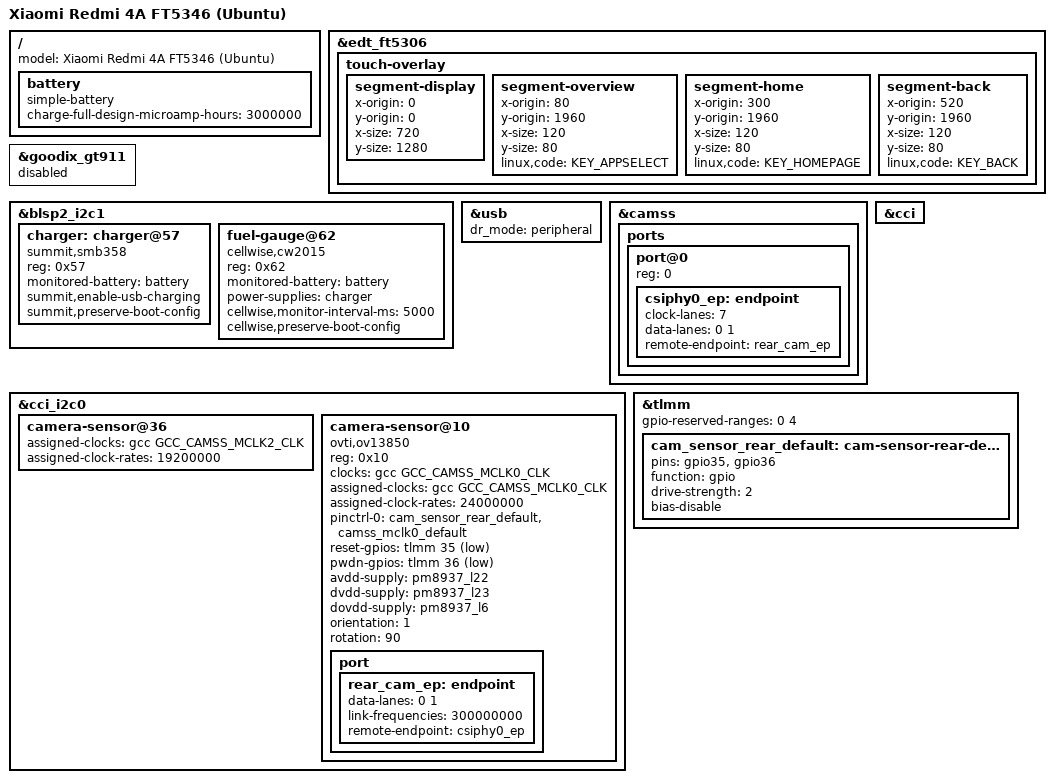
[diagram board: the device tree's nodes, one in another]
// SPDX-License-Identifier: GPL-2.0-only
/* Complete upstream rolex platform with this phone's board differences. */
#include "msm8917-xiaomi-rolex.dts"

/ {
	model = "Xiaomi Redmi 4A FT5346 (Ubuntu)";

	battery: battery {
		compatible = "simple-battery";
		charge-full-design-microamp-hours = <3000000>;
	};
};

&edt_ft5306 {
	status = "okay";

	/* FT5346 firmware reports printed keys at Y=2000, outside the LCD. */
	touch-overlay {
		segment-display {
			x-origin = <0>;
			y-origin = <0>;
			x-size = <720>;
			y-size = <1280>;
		};
		segment-overview {
			x-origin = <80>;
			y-origin = <1960>;
			x-size = <120>;
			y-size = <80>;
			linux,code = <KEY_APPSELECT>;
		};
		segment-home {
			x-origin = <300>;
			y-origin = <1960>;
			x-size = <120>;
			y-size = <80>;
			linux,code = <KEY_HOMEPAGE>;
		};
		segment-back {
			x-origin = <520>;
			y-origin = <1960>;
			x-size = <120>;
			y-size = <80>;
			linux,code = <KEY_BACK>;
		};
	};
};

&goodix_gt911 {
	status = "disabled";
};

&blsp2_i2c1 {
	status = "okay";

	charger: charger@57 {
		compatible = "summit,smb358";
		reg = <0x57>;
		monitored-battery = <&battery>;
		summit,enable-usb-charging;
		summit,preserve-boot-config;
	};

	fuel-gauge@62 {
		compatible = "cellwise,cw2015";
		reg = <0x62>;
		monitored-battery = <&battery>;
		power-supplies = <&charger>;
		cellwise,monitor-interval-ms = <5000>;
		cellwise,preserve-boot-config;
	};
};

&usb {
	dr_mode = "peripheral";
};

&camss {
	status = "okay";
	ports {
		port@0 {
			reg = <0>;
			csiphy0_ep: endpoint {
				clock-lanes = <7>;
				data-lanes = <0 1>;
				remote-endpoint = <&rear_cam_ep>;
			};
		};
	};
};

&cci {
	status = "okay";
};

&cci_i2c0 {
	/* The upstream front sensor requires a 19.2 MHz MCLK. */
	camera-sensor@36 {
		assigned-clocks = <&gcc GCC_CAMSS_MCLK2_CLK>;
		assigned-clock-rates = <19200000>;
	};

	/* OEM rear camera: CCI0, 8-bit address 0x20, MCLK0 and CSI0. */
	camera-sensor@10 {
		compatible = "ovti,ov13850";
		reg = <0x10>;
		clocks = <&gcc GCC_CAMSS_MCLK0_CLK>;
		clock-names = "xvclk";
		assigned-clocks = <&gcc GCC_CAMSS_MCLK0_CLK>;
		assigned-clock-rates = <24000000>;
		pinctrl-0 = <&cam_sensor_rear_default>, <&camss_mclk0_default>;
		pinctrl-names = "default";
		reset-gpios = <&tlmm 35 GPIO_ACTIVE_LOW>;
		pwdn-gpios = <&tlmm 36 GPIO_ACTIVE_LOW>;
		avdd-supply = <&pm8937_l22>;
		dvdd-supply = <&pm8937_l23>;
		dovdd-supply = <&pm8937_l6>;
		orientation = <1>;
		rotation = <90>;
		port {
			rear_cam_ep: endpoint {
				data-lanes = <0 1>;
				link-frequencies = /bits/ 64 <300000000>;
				remote-endpoint = <&csiphy0_ep>;
			};
		};
	};
};

/* Avoid the GPIO 0 access abort on this phone's installed firmware. */
&tlmm {
	gpio-reserved-ranges = <0 4>;
	cam_sensor_rear_default: cam-sensor-rear-default-state {
		pins = "gpio35", "gpio36";
		function = "gpio";
		drive-strength = <2>;
		bias-disable;
	};
};
